AUTOSAR XML (schema 00045)
package /MICROSAR/Det_swc/Interfaces
  client server interface DETServiceLegacy: is-service=true, service-kind=DEVELOPMENT-ERROR-TRACER
    operation ReportError: possible-error=DETServiceLegacy/E_OK
      arg InstanceId: type=uint8, direction=IN
      arg ApiId: type=uint8, direction=IN
      arg ErrorId: type=uint8, direction=IN
    error E_OK: error-code=0
  client server interface DETService: is-service=true, service-kind=DEVELOPMENT-ERROR-TRACER
    operation ReportError: possible-error=DETService/E_OK
      arg ApiId: type=uint8, direction=IN
      arg ErrorId: type=uint8, direction=IN
    operation ReportRuntimeError: possible-error=DETService/E_OK
      arg ApiId: type=uint8, direction=IN
      arg ErrorId: type=uint8, direction=IN
    error E_OK: error-code=0
package /MICROSAR/Det_swc/ComponentTypes
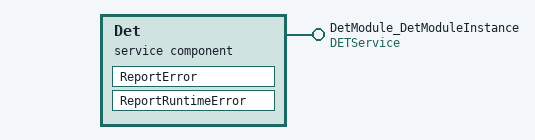
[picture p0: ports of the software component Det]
  service sw component type Det: category=SERVICE_COMPONENT
    provide port DetModule_DetModuleInstance: provided-interface=DETService
    behavior DetInternalBehavior: handle-termination-and-restart=NO-SUPPORT, port-api-option{enable-take-address=true, indirect-api=false, port-arg-values=[{value=4096, value-type=uint16}, {value=0, value-type=uint8}], port=DetModule_DetModuleInstance}
      operation invoked event OpEventReportError_ReportError_DetModule_DetModuleInstance: start-on-event=ReportError, operation=DetModule_DetModuleInstance.ReportError
      operation invoked event OpEventReportRuntimeError_ReportRuntimeError_DetModule_DetModuleInstance: start-on-event=ReportRuntimeError, operation=DetModule_DetModuleInstance.ReportRuntimeError
      runnable ReportError: can-be-invoked-concurrently=true, symbol=Det_ReportError
      runnable ReportRuntimeError: can-be-invoked-concurrently=true, symbol=Det_ReportRuntimeError
  swc implementation DetImplementation: programming-language=C, behavior=DetInternalBehavior
